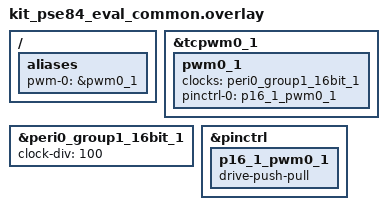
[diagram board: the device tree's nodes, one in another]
/*
 * SPDX-FileCopyrightText: Copyright (c) 2026 Infineon Technologies AG,
 * SPDX-FileCopyrightText: or an affiliate of Infineon Technologies AG. All rights reserved.
 *
 * SPDX-License-Identifier: Apache-2.0
 */

/ {
	aliases {
		pwm-0 = &pwm0_1;
	};
};

&tcpwm0_1 {
	status = "okay";

	pwm0_1: pwm0_1 {
		clocks = <&peri0_group1_16bit_1>;
		pinctrl-0 = <&p16_1_pwm0_1>;
		pinctrl-names = "default";
		status = "okay";
	};
};

&peri0_group1_16bit_1 {
	clock-div = <100>;
	status = "okay";
};

&pinctrl {
	p16_1_pwm0_1: p16_1_pwm0_1 {
		drive-push-pull;
	};
};
